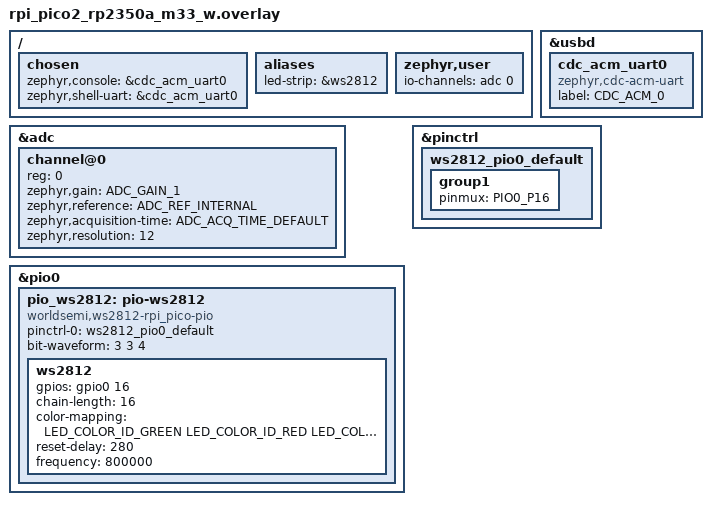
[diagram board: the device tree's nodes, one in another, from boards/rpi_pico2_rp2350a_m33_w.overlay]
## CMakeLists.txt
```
# SPDX-License-Identifier: Apache-2.0

cmake_minimum_required(VERSION 3.20.0)

find_package(Zephyr REQUIRED HINTS $ENV{ZEPHYR_BASE})
project(application)

target_include_directories(app PRIVATE ${CMAKE_CURRENT_SOURCE_DIR}/inc)

file(GLOB_RECURSE APP_SOURCES CONFIGURE_DEPENDS
    src/*.c
    src/*.cpp
)
target_sources(app PRIVATE ${APP_SOURCES})
```

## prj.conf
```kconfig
CONFIG_CPP=y
CONFIG_REQUIRES_FULL_LIBCPP=y

# POSIX API com suporte a threads
CONFIG_POSIX_API=y
CONFIG_DYNAMIC_THREAD=y
CONFIG_THREAD_STACK_INFO=y
CONFIG_DEBUG_THREAD_INFO=y
CONFIG_DYNAMIC_THREAD_POOL_SIZE=6
CONFIG_POSIX_THREAD_THREADS_MAX=6

# Console via UART (redirecionado para USB CDC no overlay)
CONFIG_CONSOLE=y
CONFIG_PRINTK=y
CONFIG_STDOUT_CONSOLE=y

# Logs
CONFIG_LOG=y
CONFIG_LOG_DEFAULT_LEVEL=1
CONFIG_LOG_BUFFER_SIZE=32768

# ADC — CONFIG_ADC=y keeps the #ifdef CONFIG_ADC guards in main.cpp/adc.c.
# ADC_RPI_PICO (default y) provides hardware/adc.h via PICOSDK_USE_ADC.
# NOTE: PICOSDK_USE_ADC has no Kconfig prompt — do NOT set it directly here.
CONFIG_ADC=y

# DMA — Zephyr API used by adc.c; &dma in the overlay selects DMA_RPI_PICO.
CONFIG_DMA=y

# DSP — floating point for sqrtf
CONFIG_FPU=y
CONFIG_FP_HARDABI=y
```

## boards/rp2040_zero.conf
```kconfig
# RP2040 Zero - LED WS2812
CONFIG_LED_STRIP=y

#USB
CONFIG_USB_DEVICE_STACK=y
CONFIG_UART_CONSOLE=y
CONFIG_USB_DEVICE_PRODUCT="Zephyr CDC ACM"
CONFIG_USB_DEVICE_MANUFACTURER="Zephyr Project"
CONFIG_USB_DEVICE_VID=0x2E8A
CONFIG_USB_DEVICE_PID=0x000A
CONFIG_USB_DEVICE_INITIALIZE_AT_BOOT=y
#CDC ACM
CONFIG_USB_CDC_ACM=y
```

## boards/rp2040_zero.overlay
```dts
/ {
    chosen {
        zephyr,console = &cdc_acm_uart0;
        zephyr,shell-uart = &cdc_acm_uart0;
    };
    zephyr,user {
        /* ADC channel 0 → GP26 */
        io-channels = <&adc 0>;
    };
};

&adc {
    status = "okay";
    #address-cells = <1>;
    #size-cells = <0>;

    channel@0 {
        reg = <0>;
        zephyr,gain = "ADC_GAIN_1";
        zephyr,reference = "ADC_REF_INTERNAL";
        zephyr,acquisition-time = <ADC_ACQ_TIME_DEFAULT>;
        zephyr,resolution = <12>;
    };
};

&usbd {
    cdc_acm_uart0: cdc_acm_uart0 {
        compatible = "zephyr,cdc-acm-uart";
    };
};

/* Enable the RP2040 DMA controller — required by adc.c (Zephyr DMA API). */
&dma {
    status = "okay";
};
```

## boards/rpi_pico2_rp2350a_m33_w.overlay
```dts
#include <zephyr/dt-bindings/led/led.h>

/ {
    chosen {
        zephyr,console = &cdc_acm_uart0;
        zephyr,shell-uart = &cdc_acm_uart0;
    };
    aliases {
        led-strip = &ws2812;
    };
    zephyr,user {
        /* ADC channel 0 → GP26 */
        io-channels = <&adc 0>;
    };
};

&adc {
    status = "okay";
    #address-cells = <1>;
    #size-cells = <0>;

    channel@0 {
        reg = <0>;
        zephyr,gain = "ADC_GAIN_1";
        zephyr,reference = "ADC_REF_INTERNAL";
        zephyr,acquisition-time = <ADC_ACQ_TIME_DEFAULT>;
        zephyr,resolution = <12>;
    };
};

&usbd {
    cdc_acm_uart0: cdc_acm_uart0 {
        compatible = "zephyr,cdc-acm-uart";
        label = "CDC_ACM_0";
    };
};

&pio0 { status = "okay"; };

/* WS2812B via PIO: nó pai (PIO) + nó filho (strip) */
&pio0 {
    pio_ws2812: pio-ws2812 {
        compatible = "worldsemi,ws2812-rpi_pico-pio";
        status = "okay";
        pinctrl-0 = <&ws2812_pio0_default>;
        pinctrl-names = "default";
        bit-waveform = <3 3 4>;

        ws2812: ws2812 {
            status = "okay";
            gpios = <&gpio0 16 GPIO_ACTIVE_HIGH>;
            chain-length = <16>;
            color-mapping = <LED_COLOR_ID_GREEN LED_COLOR_ID_RED LED_COLOR_ID_BLUE>;
            reset-delay = <280>;
            frequency = <800000>;
        };
    };
};

&pinctrl {
    ws2812_pio0_default: ws2812_pio0_default {
        group1 {
            pinmux = <PIO0_P16>;   /* GP16 em função PIO0 */
        };
    };
};
```

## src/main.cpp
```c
/*
 * Copyright (c) 2015-2016 Wind River Systems, Inc.
 *
 * Licensed under the Apache License, Version 2.0 (the "License");
 * you may not use this file except in compliance with the License.
 * You may obtain a copy of the License at
 *
 *     http://www.apache.org/licenses/LICENSE-2.0
 */

 /******************************************************************************************************
 * Include Section
 *****************************************************************************************************/


 #include <zephyr/kernel.h>
#include <zephyr/device.h>
#include <zephyr/sys/printk.h>
#include <zephyr/devicetree.h>

/** Tasks includes */
#include <tasks.h>
#include <led_service.h>
#include <dsp/adc.h>
#include <dsp/dsp.h>

/** Standard POSIX API */
#include <unistd.h>


/******************************************************************************************************
 * Application Section
 *****************************************************************************************************/

static const TaskSpec g_task_specs[] = {
#ifdef CONFIG_LED_STRIP
    { "led",  &LED_Thread,  0, SCHED_FIFO, true },
#endif
#ifdef CONFIG_ADC
    { "adc",  &ADC_Thread,  5, SCHED_FIFO, true },
    { "dsp",  &DSP_Thread,  4, SCHED_FIFO, true, (void *)&adc_pipe },
#endif
};

int main(void)
{
    k_sleep(K_MSEC(1000));

    printk("===================================\n");
    printk("Hello World! Board: %s\n", CONFIG_BOARD);
    printk("===================================\n");

    const int tasks_ret = TASKS_Init(
        g_task_specs,
        static_cast<int>(sizeof(g_task_specs) / sizeof(g_task_specs[0])));

    if (tasks_ret != 0) 
    {
        printk("TASKS_Init falhou: %d\n", tasks_ret);
    }

    return 0;
}
```

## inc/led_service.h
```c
/*
 * Copyright (c) 2026
 * Author: Eder Knoner
 * Email: eder.knoner@ostermayer.com.br
 *
 * SPDX-License-Identifier: Apache-2.0
 */

#pragma once

#include <zephyr/kernel.h>
#include <zephyr/drivers/led_strip.h>

#ifdef __cplusplus
extern "C" {
#endif

/******************************************************************************************************
 * Board-specific configuration
 *****************************************************************************************************/

#if defined(CONFIG_BOARD_RP2040_ZERO)
    /** Number of WS2812 pixels on target board. */
    #define LED_STRIP_PIXELS 1
#elif defined(CONFIG_BOARD_RPI_PICO2_RP2350A_M33_W)
    /** Number of WS2812 pixels on target board. */
    #define LED_STRIP_PIXELS 16
#else
    #define LED_STRIP_PIXELS 0
#endif

/******************************************************************************************************
 * Public API
 *****************************************************************************************************/

/**
 * @brief Initialise the LED strip service.
 *
 * Binds to the `ws2812` device-tree node and verifies the device
 * is ready. Must be called once before any other LED_* function.
 *
 * @return 0 on success, -ENODEV if the strip device is not ready.
 */
int LED_Init(void);

/**
 * @brief Set all pixels to a single HSV colour and push to the strip.
 *
 * @param hue        Hue in degrees [0, 359].
 * @param saturation Saturation percentage [0, 100].
 * @param value      Brightness percentage [0, 100].
 * @return 0 on success, negative errno on driver error.
 */
int LED_SetHSV(uint16_t hue, uint8_t saturation, uint8_t value);

/**
 * @brief Advance the rainbow animation by one step and push to the strip.
 *
 * Each call increments the internal hue counter.
 *
 * @return 0 on success, negative errno on driver error.
 */
int LED_RainbowTick(void);

/**
 * @brief POSIX thread entry that runs the continuous rainbow animation.
 *
 * Intended to be registered as a `TaskSpec::entry` in the application
 * task table. Loops forever; does not return.
 *
 * @param arg Unused.
 * @return NULL (never reached under normal operation).
 */
void *LED_Thread(void *arg);

#ifdef __cplusplus
}
#endif
```

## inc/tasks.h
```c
/*
 * Copyright (c) 2026
 * Author: Eder Knoner
 * Email: eder.knoner@ostermayer.com.br
 *
 * SPDX-License-Identifier: Apache-2.0
 */

#pragma once

#include <zephyr/kernel.h>
#include <zephyr/posix/pthread.h>

/**
 * @brief Declarative task specification consumed by `TASKS_Init()`.
 *
 * The application (for example in `main.cpp`) owns the thread entry
 * functions and provides an array of this struct to the tasks module.
 */
struct TaskSpec {
    /** Task name used for diagnostics/logging. */
    const char* name;
    /** POSIX thread entry function. */
    void* (*entry)(void*);
    /** Scheduler priority (for example with `SCHED_FIFO`). */
    int prio;
    /** POSIX scheduler policy (for example `SCHED_FIFO`). */
    int policy;
    /** Enables/disables task creation for this entry. */
    bool enabled;
    /** Optional argument forwarded verbatim to the thread entry function. */
    void *arg;
};

/**
 * @brief Runtime metadata of created tasks.
 */
struct TaskHandle {
    /** Task name copied from `TaskSpec::name`. */
    const char* name;
    /** POSIX thread identifier returned by `pthread_create()`. */
    pthread_t tid;
};


/**
 * @brief Creates and starts all enabled tasks from a user-provided list.
 *
 * @param specs Pointer to a valid array of `TaskSpec`.
 * @param spec_count Number of entries in `specs`.
 * @return 0 on success, negative errno-like value on failure.
 */
int TASKS_Init(const TaskSpec* specs, int spec_count);
```

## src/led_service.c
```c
/*
 * Copyright (c) 2026
 * Author: Eder Knoner
 * Email: eder.knoner@ostermayer.com.br
 *
 * SPDX-License-Identifier: Apache-2.0
 */

/******************************************************************************************************
 * Include Section
 *****************************************************************************************************/

#include <led_service.h>

#include <zephyr/device.h>
#include <zephyr/devicetree.h>
#include <zephyr/sys/printk.h>

#include <unistd.h>
#include <errno.h>

#ifdef CONFIG_LED_STRIP

/******************************************************************************************************
 * Private state
 *****************************************************************************************************/

static const struct device *s_strip;
static struct led_rgb        s_pixels[LED_STRIP_PIXELS];

/******************************************************************************************************
 * Private helpers
 *****************************************************************************************************/

/**
 * @brief Convert HSV to RGB.
 *
 * @param hue        Hue in degrees [0, 359].
 * @param saturation Saturation percentage [0, 100].
 * @param value      Brightness percentage [0, 100].
 * @param rgb        Output RGB pixel.
 */
static void hsv_to_rgb(uint16_t hue, uint8_t saturation, uint8_t value,
                       struct led_rgb *rgb)
{
    uint8_t region, remainder, p, q, t;

    if (saturation == 0U) {
        rgb->r = rgb->g = rgb->b = (uint8_t)(value * 255U / 100U);
        return;
    }

    region    = (uint8_t)(hue / 60U);
    remainder = (uint8_t)((hue % 60U) * 255U / 60U);

    p = (uint8_t)(value * (100U - saturation) / 100U);
    q = (uint8_t)(value * (100U - (saturation * remainder) / 255U) / 100U);
    t = (uint8_t)(value * (100U - (saturation * (255U - remainder)) / 255U) / 100U);

    value = (uint8_t)(value * 255U / 100U);
    p     = (uint8_t)(p     * 255U / 100U);
    q     = (uint8_t)(q     * 255U / 100U);
    t     = (uint8_t)(t     * 255U / 100U);

    switch (region) {
    case 0:  rgb->r = value; rgb->g = t;     rgb->b = p;     break;
    case 1:  rgb->r = q;     rgb->g = value; rgb->b = p;     break;
    case 2:  rgb->r = p;     rgb->g = value; rgb->b = t;     break;
    case 3:  rgb->r = p;     rgb->g = q;     rgb->b = value; break;
    case 4:  rgb->r = t;     rgb->g = p;     rgb->b = value; break;
    default: rgb->r = value; rgb->g = p;     rgb->b = q;     break;
    }
}

/******************************************************************************************************
 * Public API
 *****************************************************************************************************/

int LED_Init(void)
{
    s_strip = DEVICE_DT_GET(DT_NODELABEL(ws2812));

    if (!device_is_ready(s_strip)) {
        printk("LED service: strip device not ready\n");
        s_strip = NULL;
        return -ENODEV;
    }

    printk("LED service: initialised (%d pixel(s))\n", LED_STRIP_PIXELS);
    return 0;
}

int LED_SetHSV(uint16_t hue, uint8_t saturation, uint8_t value)
{
    if (s_strip == NULL) {
        return -ENODEV;
    }

    for (int i = 0; i < LED_STRIP_PIXELS; i++) {
        hsv_to_rgb(hue, saturation, value, &s_pixels[i]);
    }

    return led_strip_update_rgb(s_strip, s_pixels, LED_STRIP_PIXELS);
}

int LED_RainbowTick(void)
{
    static uint16_t s_hue = 0U;

    if (s_strip == NULL) {
        return -ENODEV;
    }

    for (int i = 0; i < LED_STRIP_PIXELS; i++) {
        s_hue = (s_hue + 1U) % 360U;
        hsv_to_rgb(s_hue, 80U, 4U, &s_pixels[i]);
    }

    return led_strip_update_rgb(s_strip, s_pixels, LED_STRIP_PIXELS);
}

void *LED_Thread(void *arg)
{
    (void)arg;

    if (LED_Init() != 0) {
        return NULL;
    }

    printk("LED thread: rainbow started\n");

    while (1) {
        (void)LED_RainbowTick();
        usleep(2000U * LED_STRIP_PIXELS);
    }

    return NULL;
}

#endif /* CONFIG_LED_STRIP */
```

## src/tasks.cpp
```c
/*
 * Copyright (c) 2026
 * Author: Eder Knoner
 * Email: eder.knoner@ostermayer.com.br
 * 
 * SPDX-License-Identifier: Apache-2.0
 */

/** Include of this module */
#include <tasks.h>

/** Zephyr includes */
#include <zephyr/kernel.h>
#include <zephyr/sys/printk.h>
#include <zephyr/posix/pthread.h>

/** Standard includes */
#include <errno.h>

/**
 * @file tasks.cpp
 * @brief Task orchestration module.
 *
 * Responsibilities:
 * - Receive task definitions from application layer (`main.cpp`).
 * - Create POSIX threads with `pthread_create(..., NULL, ...)`.
 * - Apply scheduling with `pthread_setschedparam()` after creation.
 * - Keep minimal runtime handles.
 */

static constexpr int TASKS_MAX = 8;

// ----------------- State/handles -----------------
static TaskHandle g_handles[TASKS_MAX];
static int  g_created = 0;
static bool g_started = false;

// ----------------- Creation Helper -----------------
/**
 * @brief Internal helper to create a single POSIX thread from a `TaskSpec`.
 */
static int create_thread(const TaskSpec& spec, pthread_t* tid)
{
    struct sched_param param;
    int ret = pthread_create(tid, NULL, spec.entry, spec.arg);
    if (ret != 0) {
        return ret;
    }

    param.sched_priority = spec.prio;
    ret = pthread_setschedparam(*tid, spec.policy, &param);
    if (ret != 0) {
        return ret;
    }

#if defined(CONFIG_THREAD_NAME)
    if (spec.name != nullptr) {
        (void)pthread_setname_np(*tid, spec.name);
    }
#endif

    return ret;
}


int TASKS_Init(const TaskSpec* specs, int spec_count)
{
    /* Idempotent behaviour: calling again after success is a no-op. */
    if (g_started) 
    {
        return 0;
    }

    /* Validate arguments from the application layer. */
    if ((specs == nullptr) || (spec_count <= 0)) 
    {
        return -EINVAL;
    }

    /* Bound check against fixed internal runtime storage. */
    if (spec_count > TASKS_MAX) 
    {
        return -ENOMEM;
    }

    g_created = 0;

    for (int i = 0; i < spec_count; ++i) 
    {
        if (!specs[i].enabled) 
        {
            continue;
        }

        if (specs[i].entry == nullptr)
        {
            printk("Failed to create thread '%s': null entry\n",
                   (specs[i].name != nullptr) ? specs[i].name : "(null)");
            return -EINVAL;
        }

        const int ret = create_thread(specs[i], &g_handles[g_created].tid);
        if (ret != 0)
        {
            printk("Failed to create thread '%s': %d\n", specs[i].name, ret);
            return -ret;
        }

        g_handles[g_created].name = specs[i].name;
        g_created++;
    }

    g_started = true;
    printk("TASKS_Init: %d thread(s) started\n", g_created);

    return 0;
}
```
